# cpsw_cpts register map
Vendor: Texas Instruments
Peripheral module from a debugger description file (folder am335x).
Registers are 32-bit, access per field, no defined reset value unless marked. A register's access mark holds for its fields unless they carry their own. Offsets are as the file gives them; lines under a group give offsets from that group; [hi:lo] are bit positions; {n}, {i} and the like mark numbered series; 'fields as' and 'values as' point back to an identical list; <NAME> marks a mode.

## cpsw_cpts
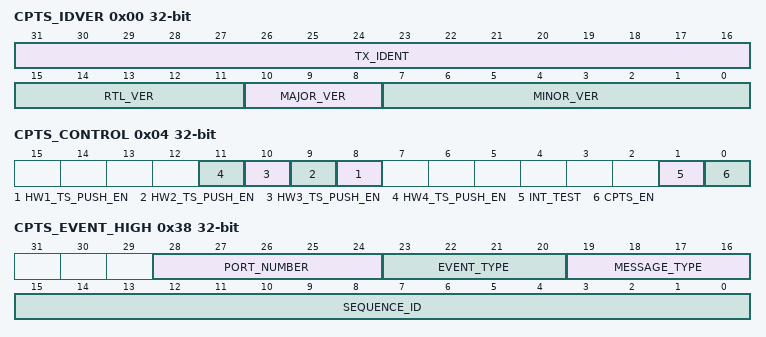
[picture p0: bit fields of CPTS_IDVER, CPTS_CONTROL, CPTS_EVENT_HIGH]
0x00 CPTS_IDVER ro — IDENTIFICATION AND VERSION REGISTER
  [31:16] TX_IDENT — TX Identification Value
  [15:11] RTL_VER — RTL Version Value
  [10:8] MAJOR_VER — Major Version Value
  [7:0] MINOR_VER — Minor Version Value
0x04 CPTS_CONTROL — TIME SYNC CONTROL REGISTER
  [n+7] HW{n}_TS_PUSH_EN rw (n=1..4) — Hardware push {n} enable
  [1] INT_TEST rw — Interrupt Test - When set, this bit allows the raw interrupt to be written to facilitate interrupt test.
  [0] CPTS_EN rw — Time Sync Enable - When disabled (cleared to zero), the RCLK domain is held in reset. 0 - Time Sync Disabled 1 - Time Sync Enabled
0x0C CPTS_TS_PUSH — TIME STAMP EVENT PUSH REGISTER
  [0] TS_PUSH wo — Time stamp event push - When a logic high is written to this bit a time stamp event is pushed onto the event FIFO. The time stamp value is the time of the write of this register, not the time of the event read. The time stamp value can then be read on interrupt via the event registers. Software should not push a second time stamp event onto the event FIFO until the first time stamp value has been read from the event FIFO (there should be only one time stamp event in the event FIFO at any given time). This bit is write only and always reads zero.
0x10 CPTS_TS_LOAD_VAL rw — TIME STAMP LOAD VALUE REGISTER
  [31:0] TS_LOAD_VAL — Time Stamp Load Value - Writing the ts_load_en bit causes the value contained in this register to be written into the time stamp. The time stamp value is read by initiating a time stamp push event, not by reading this register. When reading this register, the value read is not the time stamp, but is the value that was last written to this register.
0x14 CPTS_TS_LOAD_EN — TIME STAMP LOAD ENABLE REGISTER
  [0] TS_LOAD_EN wo — Time Stamp Load - Writing a one to this bit enables the time stamp value to be written via the ts_load_val[31:0] register. This feature is included for test purposes. This bit is write only.
0x20 CPTS_INTSTAT_RAW — TIME SYNC INTERRUPT STATUS RAW REGISTER
  [0] TS_PEND_RAW rw — TS_PEND_RAW int read (before enable). Writable when int_test = 1 A one in this bit indicates that there is one or more events in the event FIFO.
0x24 CPTS_INTSTAT_MASKED ro — TIME SYNC INTERRUPT STATUS MASKED REGISTER
  [0] TS_PEND — TS_PEND masked interrupt read (after enable).
0x28 CPTS_INT_ENABLE — TIME SYNC INTERRUPT ENABLE REGISTER
  [0] TS_PEND_EN rw — TS_PEND masked interrupt enable.
0x30 CPTS_EVENT_POP — EVENT INTERRUPT POP REGISTER
  [0] EVENT_POP wo — Event Pop - When a logic high is written to this bit an event is popped off the event FIFO. The event FIFO pop occurs as part of the interrupt process after the event has been read in the Event_Low and Event_High registers. Popping an event discards the event and causes the next event, if any, to be moved to the top of the FIFO ready to be read by software on interrupt.
0x34 CPTS_EVENT_LOW ro — LOWER 32-BITS OF THE EVENT VALUE
  [31:0] TIME_STAMP — Time Stamp - The timestamp is valid for transmit, receive, and time stamp push event types. The timestamp value is not valid for counter roll event types.
0x38 CPTS_EVENT_HIGH ro — UPPER 32-BITS OF THE EVENT VALUE
  [28:24] PORT_NUMBER — Port Number - indicates the port number of an ethernet event or the hardware push pin number (1 to 4).
  [23:20] EVENT_TYPE — Time Sync Event Type 0000 - Time Stamp Push Event 0001 - Time Stamp Rollover Event 0010 - Time Stamp Half Rollover Event 0011 - Hardware Time Stamp Push Event 0100 - Ethernet Receive Event 0101 - Ethernet Transmit Event
  [19:16] MESSAGE_TYPE — Message type - The message type value that was contained in an ethernet transmit or receive time sync packet. This field is valid only for ethernet transmit or receive events.
  [15:0] SEQUENCE_ID — Sequence ID - The 16-bit sequence id is the value that was contained in an ethernet transmit or receivetime sync packet. This field is valid only for ethernet transmit or receive events.
